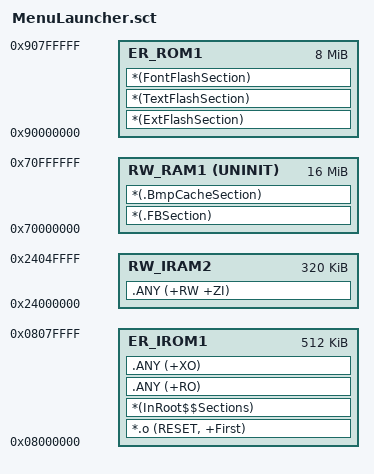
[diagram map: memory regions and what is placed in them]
; *************************************************************
; *** Scatter-Loading Description File generated by uVision ***
; *************************************************************

LR_IROM1 0x08000000 0x00080000  {    ; load region size_region
  ER_IROM1 0x08000000 0x00080000  {  ; load address = execution address
   *.o (RESET, +First)
   *(InRoot$$Sections)
   .ANY (+RO)
   .ANY (+XO)
  }
  RW_RAM1 0x70000000 UNINIT 0x01000000  {  ; RW data
   *(.FBSection)
   *(.BmpCacheSection)
  }

  RW_IRAM2 0x24000000 0x00050000  {
   .ANY (+RW +ZI)
  }
}

LR_ROM1 0x90000000 0x00800000  {
  ER_ROM1 0x90000000 0x00800000  {  ; load address = execution address
   *(ExtFlashSection)
    *(TextFlashSection)
    *(FontFlashSection) 
  }
}
